# DMASS_PKTDMA_0_PKTDMA_TXCCFG_484A0000h register map
Vendor: Texas Instruments
Peripheral module from a debugger description file (folder AM275x).
Registers are 32-bit, read-write, reset 0x0 unless marked. A register's access mark holds for its fields unless they carry their own. Offsets are as the file gives them; lines under a group give offsets from that group; [hi:lo] are bit positions; {n}, {i} and the like mark numbered series; 'fields as' and 'values as' point back to an identical list; <NAME> marks a mode.

## pktdma_txccfg
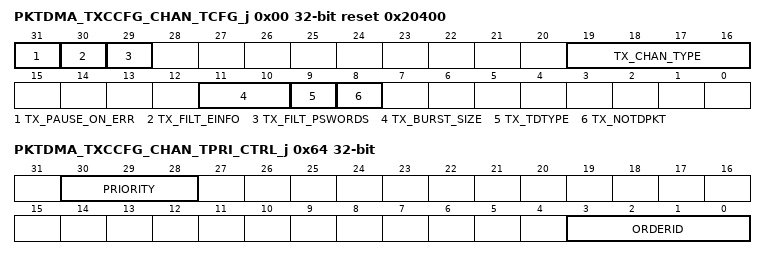
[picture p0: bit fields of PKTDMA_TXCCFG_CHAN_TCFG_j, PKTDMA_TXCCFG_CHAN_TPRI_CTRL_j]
0x00 PKTDMA_TXCCFG_CHAN_TCFG_j access per field reset 0x20400 — The Tx Channel Configuration Register is used to initialize static mode settings for the Tx DMA channel. This register may only be written when the channel is disabled (tx_enable in realtime control reg is 0).
  [31] TX_PAUSE_ON_ERR rw — Pause On Error: this field controls what the channel will do if an error or exception occurs during a data transfer. This field is encoded as follows: 0 = Channel will drop current work and move on 1 = Channel will pause and wait for SW to investigate and un-pause the channel. Reset Source: rst_mod_g_rst_n
  [30] TX_FILT_EINFO rw — This field controls whether or not the DMA controller will pass the extended packet information fields (if present) from the descriptor to the back end application. This field is encoded as follows: 0=DMA controller will pass extended packet info words if they are present in the descriptor 1=DMA controller will filter extended packet info words. Reset Source: rst_mod_g_rst_n
  [29] TX_FILT_PSWORDS rw — This field controls whether or not the DMA controller will pass the protocol specific words (if present) from the descriptor to the back end application. This field is encoded as follows: 0=DMA controller will pass PS words if present in descriptor 1=DMA controller will filter PS words. Reset Source: rst_mod_g_rst_n
  [19:16] TX_CHAN_TYPE ro — Tx Channel Type: this field controls and / or indicates the functional channel type for this channel and the work passing mechanism that the channel uses for communicating with the Host. Available channel types are as follows: 2 = Channel performs packet oriented data transfers using pass by reference rings. Channels configured in this mode can only use Host and Monolithic descriptors and the pointers to those descriptors are passed from/to SW using rings in the Ring Accelerator. Reset Source: rst_mod_g_rst_n
  [11:10] TX_BURST_SIZE rw — Specifies the nominal burst size and alignment for data transfers on this channel. 0,1 = 64 Bytes 2 = 128 Bytes All other values are reserved Reset Source: rst_mod_g_rst_n
  [9] TX_TDTYPE rw — Specifies whether or not the channel should immediately return a teardown completion response to the default completion queue or wait until a status message is returned from the remote PSI-L paired peripheral. 0 = return immediately once all traffic is complete in PKTDMA. 1 = wait until remote peer sends back a completion message. Reset Source: rst_mod_g_rst_n
  [8] TX_NOTDPKT rw — Specifies whether or not the channel should suppress sending the single data phase teardown packet when teardown is complete. 0 = TD packet is sent 1 = Suppress sending TD packet Reset Source: rst_mod_g_rst_n
0x64 PKTDMA_TXCCFG_CHAN_TPRI_CTRL_j — The priority control register is used to control the priority of the transactions which the DMA generates on it's initiator interface.
  [30:28] PRIORITY — Tx Priority: This field contains the 3-bit value which will be output on the mem*_cpriority and mem_cepriority outputs during all transactions for this channel. Reset Source: rst_mod_g_rst_n
  [3:0] ORDERID — Tx Order ID: This field contains the 4-bit value which will be output on the mem*_corderid output during all transactions for this channel. Reset Source: rst_mod_g_rst_n
0x68 PKTDMA_TXCCFG_CHAN_THREAD_j — The thread ID mapping register is used to pair the Tx DMA channel to a specific destination thread. All traffic generated from this channel will be sent with a thread_id on the PSI-L interface with the value from this register.
  [15:0] THREAD_ID — Thread ID: This field contains the (up-to) 16-bit value which will be output on the strm_o_thread_id output during all transactions for this channel. Reset Source: rst_mod_g_rst_n
0x70 PKTDMA_TXCCFG_CHAN_TFIFO_DEPTH_j reset 0xC0 — The fifo depth register is used to specify how many FIFO data phases deep the Tx per channel FIFO will be for the channel. While the maximum depth of the Tx FIFO is set at design time, the FIFO depth can be artificially reduced in order to control the maximum latency which can be introduced due to buffering effects.
  [7:0] FDEPTH — FIFO Depth: This field contains the number of Tx FIFO bytes which will be allowed to be stored for the channel. The minimum value is equal to the PSI-L interface data path width but must be greater than 32 bytes + the burst size, the maximum value varies by channel class (ultra-high capacity/high capacity/normal capacity) and is equal to the tubuf_size/thbuf_size/tbuf_size parameter respectively multiplied by the PSI-L data path width (tstrm_wdth). The fdepth must always be an integer multiple of tstrm_wdth. The reset value of this register varies by channel class (ultra-high capacity/high capacity/normal capacity) but will be equal to the tubuf_size/thbuf_size/tbuf_size parameter respectively multiplied by the PSI-L interface data width (tstrm_wdth). Reset Source: rst_mod_g_rst_n
0x80 PKTDMA_TXCCFG_CHAN_TST_SCHED_j — The Tx Channel N Static Scheduler Configuration Register contains static configuration information which affects the conditions under which each channel will be given an opportunity to use the Tx DMA unit(s). The fields in this register are as follows:
  [1:0] PRIORITY — Tx Scheduling Priority: These bits select which scheduling bin the channel will be placed in for bandwidth allocation of the Tx DMA units. This field is encoded as follows: 0 = High priority 1 = Medium - high priority 2 = Medium - low priority 3 = Low priority Arbitration between bins is performed in a strict priority fashion. High priority channels will always be serviced first. If no high priority channels are requesting then all medium-high priority channels will be serviced next. If no high priority or medium-high priority channels are requesting then all medium-low priority channels will be serviced next. When no other channels are requesting, the low priority channels will be serviced. All channels within a given bin are serviced in a round robin order. Only channels which are enabled and which have sufficient free space in their Per Channel FIFO will be included in the round robin arbitration. Reset Source: rst_mod_g_rst_n
